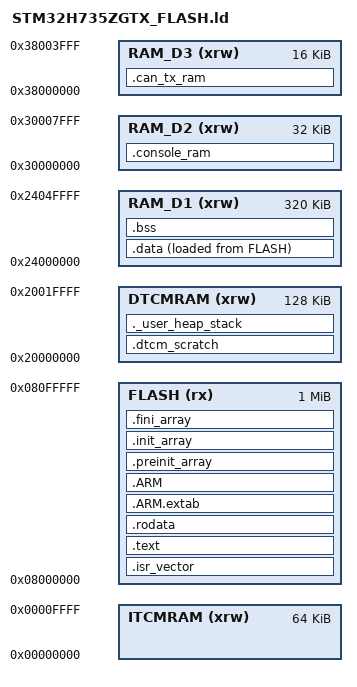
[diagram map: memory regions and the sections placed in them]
/*
******************************************************************************
**
**  File        : LinkerScript.ld
**
**  Author      : STM32CubeIDE
**
**  Abstract    : Linker script for STM32H7 series
**                1024Kbytes FLASH and 560Kbytes RAM
**
**                Set heap size, stack size and stack location according
**                to application requirements.
**
**                Set memory bank area and size if external memory is used.
**
**  Target      : STMicroelectronics STM32
**
**  Distribution: The file is distributed as is, without any warranty
**                of any kind.
**
*****************************************************************************
** @attention
**
** Copyright (c) 2026 STMicroelectronics.
** All rights reserved.
**
** This software is licensed under terms that can be found in the LICENSE file
** in the root directory of this software component.
** If no LICENSE file comes with this software, it is provided AS-IS.
**
****************************************************************************
*/

/* Entry Point */
ENTRY(Reset_Handler)

/* Highest address of the user mode stack. Keep the CPU stack in DTCM. */
_estack = ORIGIN(DTCMRAM) + LENGTH(DTCMRAM);
/* Generate a link error if heap and stack don't fit into RAM */
_Min_Heap_Size = 0x200;      /* required amount of heap  */
_Min_Stack_Size = 0x2000;    /* reserve 8 KiB for the MSP stack */

/* Specify the memory areas */
MEMORY
{
  ITCMRAM (xrw)    : ORIGIN = 0x00000000,   LENGTH = 64K
  DTCMRAM (xrw)    : ORIGIN = 0x20000000,   LENGTH = 128K
  FLASH    (rx)    : ORIGIN = 0x08000000,   LENGTH = 1024K
  RAM_D1  (xrw)    : ORIGIN = 0x24000000,   LENGTH = 320K
  RAM_D2  (xrw)    : ORIGIN = 0x30000000,   LENGTH = 32K
  RAM_D3  (xrw)    : ORIGIN = 0x38000000,   LENGTH = 16K
}

/* Define output sections */
SECTIONS
{
  /* The startup code goes first into FLASH */
  .isr_vector :
  {
    . = ALIGN(4);
    KEEP(*(.isr_vector)) /* Startup code */
    . = ALIGN(4);
  } >FLASH

  /* The program code and other data goes into FLASH */
  .text :
  {
    . = ALIGN(4);
    *(.text)           /* .text sections (code) */
    *(.text*)          /* .text* sections (code) */
    *(.glue_7)         /* glue arm to thumb code */
    *(.glue_7t)        /* glue thumb to arm code */
    *(.eh_frame)

    KEEP (*(.init))
    KEEP (*(.fini))

    . = ALIGN(4);
    _etext = .;        /* define a global symbols at end of code */
  } >FLASH

  /* Constant data goes into FLASH */
  .rodata :
  {
    . = ALIGN(4);
    *(.rodata)         /* .rodata sections (constants, strings, etc.) */
    *(.rodata*)        /* .rodata* sections (constants, strings, etc.) */
    . = ALIGN(4);
  } >FLASH

  .ARM.extab : /* The READONLY keyword is only supported in GCC11 and later, remove it if using GCC10 or earlier. */
  {
    *(.ARM.extab* .gnu.linkonce.armextab.*)
  } >FLASH
  .ARM : /* The READONLY keyword is only supported in GCC11 and later, remove it if using GCC10 or earlier. */
  {
    __exidx_start = .;
    *(.ARM.exidx*)
    __exidx_end = .;
  } >FLASH

  .preinit_array : /* The READONLY keyword is only supported in GCC11 and later, remove it if using GCC10 or earlier. */
  {
    PROVIDE_HIDDEN (__preinit_array_start = .);
    KEEP (*(.preinit_array*))
    PROVIDE_HIDDEN (__preinit_array_end = .);
  } >FLASH

  .init_array : /* The READONLY keyword is only supported in GCC11 and later, remove it if using GCC10 or earlier. */
  {
    PROVIDE_HIDDEN (__init_array_start = .);
    KEEP (*(SORT(.init_array.*)))
    KEEP (*(.init_array*))
    PROVIDE_HIDDEN (__init_array_end = .);
  } >FLASH

  .fini_array : /* The READONLY keyword is only supported in GCC11 and later, remove it if using GCC10 or earlier. */
  {
    PROVIDE_HIDDEN (__fini_array_start = .);
    KEEP (*(SORT(.fini_array.*)))
    KEEP (*(.fini_array*))
    PROVIDE_HIDDEN (__fini_array_end = .);
  } >FLASH

  /* used by the startup to initialize data */
  _sidata = LOADADDR(.data);

  /* Initialized data sections goes into RAM, load LMA copy after code */
  .data :
  {
    . = ALIGN(4);
    _sdata = .;        /* create a global symbol at data start */
    *(.data)           /* .data sections */
    *(.data*)          /* .data* sections */
    *(.RamFunc)        /* .RamFunc sections */
    *(.RamFunc*)       /* .RamFunc* sections */

    . = ALIGN(4);
    _edata = .;        /* define a global symbol at data end */
  } >RAM_D1 AT> FLASH

  /* Uninitialized data section */
  . = ALIGN(4);
  .bss :
  {
    /* This is used by the startup in order to initialize the .bss section */
    _sbss = .;         /* define a global symbol at bss start */
    __bss_start__ = _sbss;
    *(.bss)
    *(.bss*)
    *(COMMON)

    . = ALIGN(4);
    _ebss = .;         /* define a global symbol at bss end */
    __bss_end__ = _ebss;
  } >RAM_D1

  /*
   * RAM_D2 is dedicated to the non-blocking USART console.  The section is
   * NOLOAD because every message and length slot is written before DMA reads
   * it; the small console control state remains in the zeroed RAM_D1 .bss.
   */
  .console_ram (NOLOAD) :
  {
    . = ALIGN(32);
    __console_ram_start__ = .;
    KEEP(*(.console_ram))
    KEEP(*(.console_ram*))
    . = ALIGN(32);
    __console_ram_end__ = .;
  } >RAM_D2

  ASSERT(SIZEOF(.console_ram) <= LENGTH(RAM_D2),
         "Console storage exceeds dedicated RAM_D2")

  /*
   * CPU-only HyperRAM staging and destructive-test buffers. These buffers are
   * currently consumed by polling HAL_OSPI calls, not by a DMA controller.
   */
  .dtcm_scratch (NOLOAD) :
  {
    . = ALIGN(32);
    __dtcm_scratch_start__ = .;
    KEEP(*(.dtcm_scratch))
    KEEP(*(.dtcm_scratch*))
    . = ALIGN(32);
    __dtcm_scratch_end__ = .;
  } >DTCMRAM

  /* Heap origin and MSP reservation share the remaining DTCM address space. */
  ._user_heap_stack (NOLOAD) :
  {
    . = ALIGN(32);
    PROVIDE ( end = . );
    PROVIDE ( _end = . );
    . = . + _Min_Heap_Size;
    . = . + _Min_Stack_Size;
    . = ALIGN(32);
  } >DTCMRAM

  ASSERT((SIZEOF(.dtcm_scratch) + SIZEOF(._user_heap_stack)) <=
         LENGTH(DTCMRAM),
         "DTCM scratch, heap and stack reservations exceed DTCMRAM")

  /* Reserved for the planned timestamped internal CAN transmit queue. */
  .can_tx_ram (NOLOAD) :
  {
    . = ALIGN(32);
    __can_tx_ram_start__ = .;
    KEEP(*(.can_tx_ram))
    KEEP(*(.can_tx_ram*))
    . = ALIGN(32);
    __can_tx_ram_end__ = .;
  } >RAM_D3

  ASSERT(SIZEOF(.can_tx_ram) <= LENGTH(RAM_D3),
         "CAN transmit queue exceeds dedicated RAM_D3")

  /* Remove information from the standard libraries */
  /DISCARD/ :
  {
    libc.a ( * )
    libm.a ( * )
    libgcc.a ( * )
  }

  .ARM.attributes 0 : { *(.ARM.attributes) }
}
